AUTOSAR XML (schema 4-3-0)
package /ARRoot
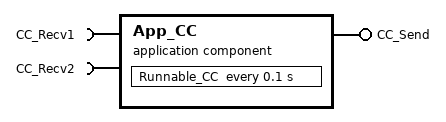
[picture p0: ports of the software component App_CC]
  application sw component type App_CC
    provide port CC_Send: provided-interface=CC_Send
      provided-com-specs:
        data-element=ACCEL, network-representation=compu-method=ISignal_CC_Send_ACCEL
        data-element=BRAKE, network-representation=compu-method=ISignal_CC_Send_BRAKE
    require port CC_Recv1: required-interface=CC_Recv1
      required-com-specs:
        data-element=ACCEL_VALUE, network-representation=compu-method=ISignal_CC_Recv1_ACCEL_VALUE
        data-element=TARGET_SPEED, network-representation=compu-method=ISignal_CC_Recv1_TARGET_SPEED
    require port CC_Recv2: required-interface=CC_Recv2
      required-com-specs:
        data-element=CC_TRIGGER, network-representation=compu-method=ISignal_CC_Recv2_CC_TRIGGER
        data-element=SPEED, network-representation=compu-method=ISignal_CC_Recv2_SPEED
    behavior InternalBehavior
      timing event TE_Runnable_CC: start-on-event=Runnable_CC, period=0.1
      runnable Runnable_CC: symbol=Runnable_CC_100ms
        data-receive-point-by-arguments:
          4 x access, all with scope=COMMUNICATION-INTER-ECU:
            DRPBA_Runnable_CC_CC_Recv1_ACCEL_VALUE: accessed-variable=CC_Recv1.ACCEL_VALUE
            DRPBA_Runnable_CC_CC_Recv1_TARGET_SPEED: accessed-variable=CC_Recv1.TARGET_SPEED
            DRPBA_Runnable_CC_CC_Recv2_CC_TRIGGER: accessed-variable=CC_Recv2.CC_TRIGGER
            DRPBA_Runnable_CC_CC_Recv2_SPEED: accessed-variable=CC_Recv2.SPEED
        data-send-points:
          access DSP_Runnable_CC_CC_Send_ACCEL: accessed-variable=CC_Send.ACCEL, scope=COMMUNICATION-INTER-ECU
          access DSP_Runnable_CC_CC_Send_BRAKE: accessed-variable=CC_Send.BRAKE, scope=COMMUNICATION-INTER-ECU
